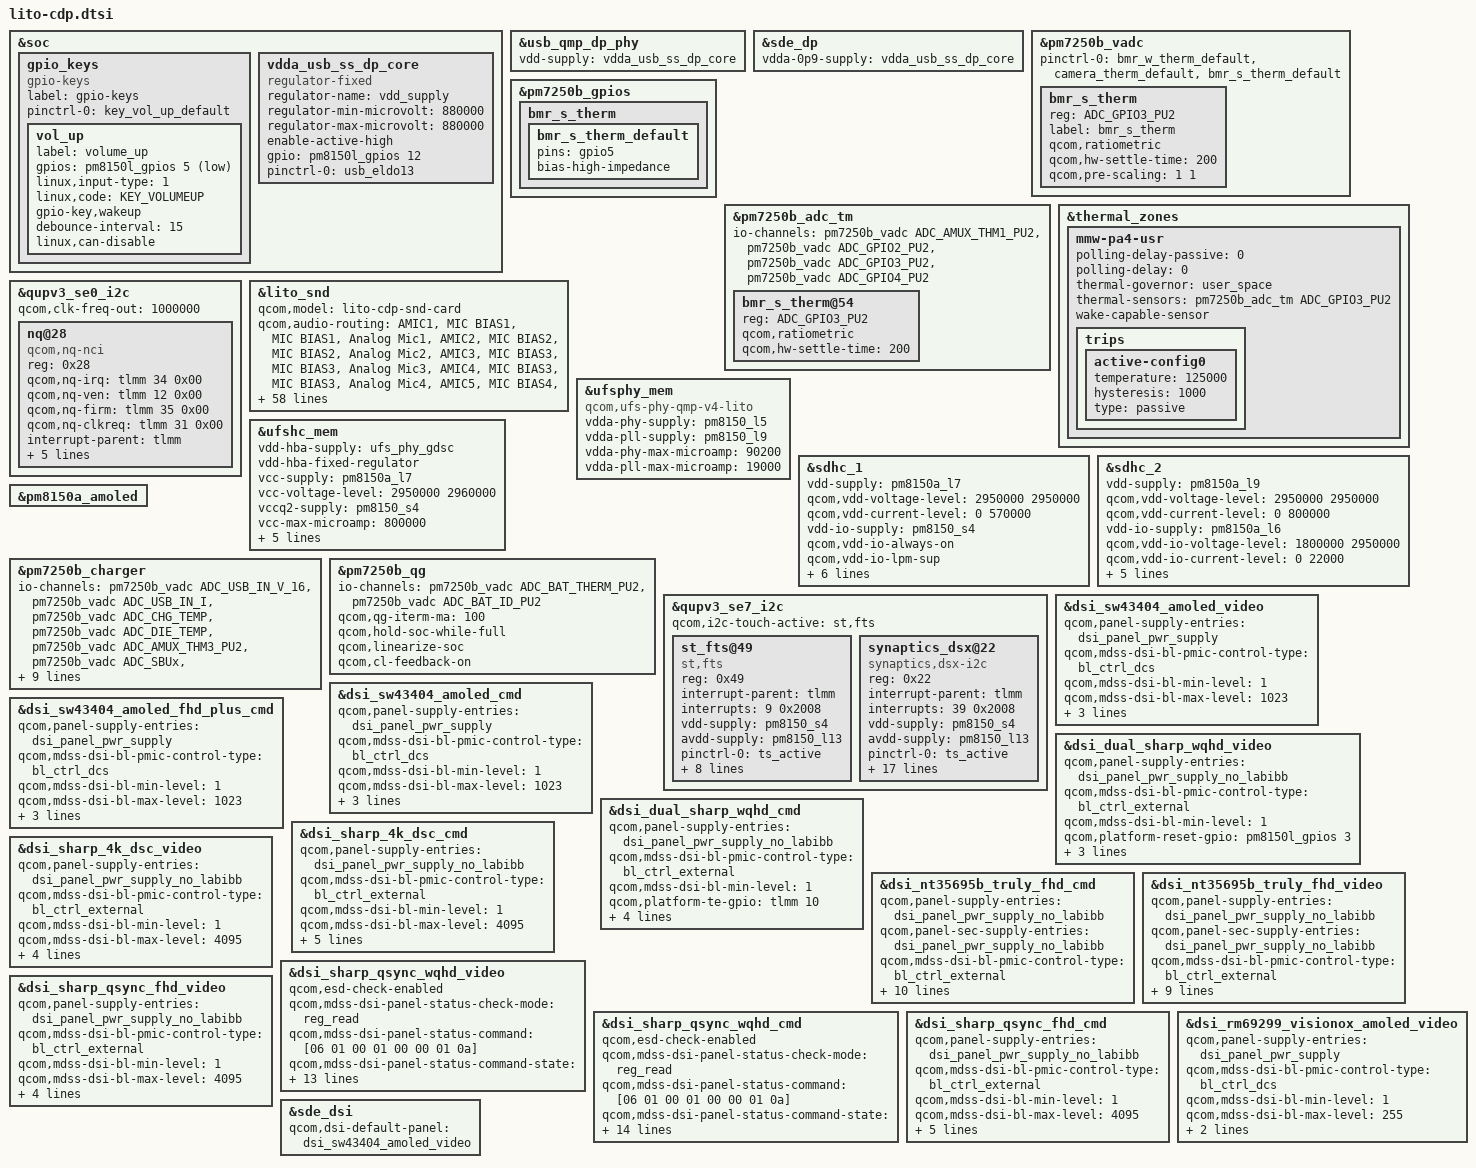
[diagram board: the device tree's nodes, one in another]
#include <dt-bindings/gpio/gpio.h>
#include "lito-audio-overlay.dtsi"
#include "lito-pmic-overlay.dtsi"
#include "camera/lito-camera-sensor-cdp.dtsi"
#include "lito-sde-display.dtsi"
#include "lito-thermal-overlay.dtsi"

&soc {
	gpio_keys {
		compatible = "gpio-keys";
		label = "gpio-keys";

		pinctrl-names = "default";
		pinctrl-0 = <&key_vol_up_default>;

		vol_up {
			label = "volume_up";
			gpios = <&pm8150l_gpios 5 GPIO_ACTIVE_LOW>;
			linux,input-type = <1>;
			linux,code = <KEY_VOLUMEUP>;
			gpio-key,wakeup;
			debounce-interval = <15>;
			linux,can-disable;
		};
	};

	vdda_usb_ss_dp_core: vdda_usb_ss_dp_core {
		compatible = "regulator-fixed";
		regulator-name = "vdd_supply";
		regulator-min-microvolt = <880000>;
		regulator-max-microvolt = <880000>;
		enable-active-high;
		gpio = <&pm8150l_gpios 12 GPIO_ACTIVE_HIGH>;
		pinctrl-names = "default";
		pinctrl-0 = <&usb_eldo13>;
	};
};

&usb_qmp_dp_phy {
	vdd-supply = <&vdda_usb_ss_dp_core>;
};

&sde_dp {
	vdda-0p9-supply = <&vdda_usb_ss_dp_core>;
};

&pm7250b_vadc {
	pinctrl-0 = <
		&bmr_w_therm_default
		&camera_therm_default
		&bmr_s_therm_default
	>;

	bmr_s_therm {
		reg = <ADC_GPIO3_PU2>;
		label = "bmr_s_therm";
		qcom,ratiometric;
		qcom,hw-settle-time = <200>;
		qcom,pre-scaling = <1 1>;
	};
};

&pm7250b_gpios {
	bmr_s_therm {
		bmr_s_therm_default: bmr_s_therm_default {
			pins = "gpio5";
			bias-high-impedance;
		};
	};
};

&pm7250b_adc_tm {
	io-channels = <&pm7250b_vadc ADC_AMUX_THM1_PU2>,
			<&pm7250b_vadc ADC_GPIO2_PU2>,
			<&pm7250b_vadc ADC_GPIO3_PU2>,
			<&pm7250b_vadc ADC_GPIO4_PU2>;

	bmr_s_therm@54 {
		reg = <ADC_GPIO3_PU2>;
		qcom,ratiometric;
		qcom,hw-settle-time = <200>;
	};
};

&thermal_zones {
	mmw-pa4-usr {
		polling-delay-passive = <0>;
		polling-delay = <0>;
		thermal-governor = "user_space";
		thermal-sensors = <&pm7250b_adc_tm ADC_GPIO3_PU2>;
		wake-capable-sensor;
		trips {
			active-config0 {
				temperature = <125000>;
				hysteresis = <1000>;
				type = "passive";
			};
		};
	};
};

&qupv3_se0_i2c {
	status = "ok";
	qcom,clk-freq-out = <1000000>;
	#address-cells = <1>;
	#size-cells = <0>;
	nq@28 {
		compatible = "qcom,nq-nci";
		reg = <0x28>;
		qcom,nq-irq = <&tlmm 34 0x00>;
		qcom,nq-ven = <&tlmm 12 0x00>;
		qcom,nq-firm = <&tlmm 35 0x00>;
		qcom,nq-clkreq = <&tlmm 31 0x00>;
		interrupt-parent = <&tlmm>;
		interrupts = <34 0>;
		interrupt-names = "nfc_irq";
		pinctrl-names = "nfc_active", "nfc_suspend";
		pinctrl-0 = <&nfc_int_active &nfc_enable_active
				&nfc_clk_req_active>;
		pinctrl-1 = <&nfc_int_suspend &nfc_enable_suspend
				&nfc_clk_req_suspend>;
	};
};

&lito_snd {
	qcom,model = "lito-cdp-snd-card";
	qcom,audio-routing =
		"AMIC1", "MIC BIAS1",
		"MIC BIAS1", "Analog Mic1",
		"AMIC2", "MIC BIAS2",
		"MIC BIAS2", "Analog Mic2",
		"AMIC3", "MIC BIAS3",
		"MIC BIAS3", "Analog Mic3",
		"AMIC4", "MIC BIAS3",
		"MIC BIAS3", "Analog Mic4",
		"AMIC5", "MIC BIAS4",
		"MIC BIAS4", "Analog Mic5",
		"TX DMIC0", "MIC BIAS3",
		"MIC BIAS3", "Digital Mic0",
		"TX DMIC1", "MIC BIAS3",
		"MIC BIAS3", "Digital Mic1",
		"TX DMIC2", "MIC BIAS1",
		"MIC BIAS1", "Digital Mic2",
		"TX DMIC3", "MIC BIAS1",
		"MIC BIAS1", "Digital Mic3",
		"TX DMIC4", "MIC BIAS4",
		"MIC BIAS4", "Digital Mic4",
		"TX DMIC5", "MIC BIAS4",
		"MIC BIAS4", "Digital Mic5",
		"DMIC1", "MIC BIAS3",
		"MIC BIAS3", "Digital Mic0",
		"DMIC2", "MIC BIAS3",
		"MIC BIAS3", "Digital Mic1",
		"DMIC3", "MIC BIAS1",
		"MIC BIAS1", "Digital Mic2",
		"DMIC4", "MIC BIAS1",
		"MIC BIAS1", "Digital Mic3",
		"DMIC5", "MIC BIAS4",
		"MIC BIAS4", "Digital Mic4",
		"DMIC6", "MIC BIAS4",
		"MIC BIAS4", "Digital Mic5",
		"DMIC7", "MIC BIAS3",
		"MIC BIAS3", "Digital Mic6",
		"DMIC8", "MIC BIAS3",
		"MIC BIAS3", "Digital Mic7",
		"IN1_HPHL", "HPHL_OUT",
		"IN2_HPHR", "HPHR_OUT",
		"IN3_AUX", "AUX_OUT",
		"TX SWR_ADC0", "ADC1_OUTPUT",
		"TX SWR_ADC1", "ADC2_OUTPUT",
		"TX SWR_ADC2", "ADC3_OUTPUT",
		"TX SWR_ADC3", "ADC4_OUTPUT",
		"TX SWR_DMIC0", "DMIC1_OUTPUT",
		"TX SWR_DMIC1", "DMIC2_OUTPUT",
		"TX SWR_DMIC2", "DMIC3_OUTPUT",
		"TX SWR_DMIC3", "DMIC4_OUTPUT",
		"TX SWR_DMIC4", "DMIC5_OUTPUT",
		"TX SWR_DMIC5", "DMIC6_OUTPUT",
		"TX SWR_DMIC6", "DMIC7_OUTPUT",
		"TX SWR_DMIC7", "DMIC8_OUTPUT",
		"WSA SRC0_INP", "SRC0",
		"WSA_TX DEC0_INP", "TX DEC0 MUX",
		"WSA_TX DEC1_INP", "TX DEC1 MUX",
		"RX_TX DEC0_INP", "TX DEC0 MUX",
		"RX_TX DEC1_INP", "TX DEC1 MUX",
		"RX_TX DEC2_INP", "TX DEC2 MUX",
		"RX_TX DEC3_INP", "TX DEC3 MUX",
		"SpkrLeft IN", "WSA_SPK1 OUT",
		"SpkrRight IN", "WSA_SPK2 OUT",
		"VA_AIF1 CAP", "VA_SWR_CLK",
		"VA_AIF2 CAP", "VA_SWR_CLK",
		"VA_AIF3 CAP", "VA_SWR_CLK",
		"VA MIC BIAS3", "Digital Mic0",
		"VA MIC BIAS3", "Digital Mic1",
		"VA MIC BIAS1", "Digital Mic2",
		"VA MIC BIAS1", "Digital Mic3",
		"VA MIC BIAS4", "Digital Mic4",
		"VA MIC BIAS4", "Digital Mic5",
		"VA DMIC0", "VA MIC BIAS3",
		"VA DMIC1", "VA MIC BIAS3",
		"VA DMIC2", "VA MIC BIAS1",
		"VA DMIC3", "VA MIC BIAS1",
		"VA DMIC4", "VA MIC BIAS4",
		"VA DMIC5", "VA MIC BIAS4",
		"VA SWR_ADC0", "VA_SWR_CLK",
		"VA SWR_ADC1", "VA_SWR_CLK",
		"VA SWR_ADC2", "VA_SWR_CLK",
		"VA SWR_ADC3", "VA_SWR_CLK",
		"VA SWR_MIC0", "VA_SWR_CLK",
		"VA SWR_MIC1", "VA_SWR_CLK",
		"VA SWR_MIC2", "VA_SWR_CLK",
		"VA SWR_MIC3", "VA_SWR_CLK",
		"VA SWR_MIC4", "VA_SWR_CLK",
		"VA SWR_MIC5", "VA_SWR_CLK",
		"VA SWR_MIC6", "VA_SWR_CLK",
		"VA SWR_MIC7", "VA_SWR_CLK",
		"VA SWR_ADC0", "ADC1_OUTPUT",
		"VA SWR_ADC1", "ADC2_OUTPUT",
		"VA SWR_ADC2", "ADC3_OUTPUT",
		"VA SWR_ADC3", "ADC4_OUTPUT",
		"VA SWR_MIC0", "DMIC1_OUTPUT",
		"VA SWR_MIC1", "DMIC2_OUTPUT",
		"VA SWR_MIC2", "DMIC3_OUTPUT",
		"VA SWR_MIC3", "DMIC4_OUTPUT",
		"VA SWR_MIC4", "DMIC5_OUTPUT",
		"VA SWR_MIC5", "DMIC6_OUTPUT",
		"VA SWR_MIC6", "DMIC7_OUTPUT",
		"VA SWR_MIC7", "DMIC8_OUTPUT";
};

&ufsphy_mem {
	compatible = "qcom,ufs-phy-qmp-v4-lito";

	vdda-phy-supply = <&pm8150_l5>;
	vdda-pll-supply = <&pm8150_l9>;
	vdda-phy-max-microamp = <90200>;
	vdda-pll-max-microamp = <19000>;

	status = "ok";
};

&ufshc_mem {
	vdd-hba-supply = <&ufs_phy_gdsc>;
	vdd-hba-fixed-regulator;
	vcc-supply = <&pm8150a_l7>;
	vcc-voltage-level = <2950000 2960000>;
	vccq2-supply = <&pm8150_s4>;
	vcc-max-microamp = <800000>;
	vccq2-max-microamp = <800000>;

	qcom,vddp-ref-clk-supply = <&pm8150_l9>;
	qcom,vddp-ref-clk-max-microamp = <100>;
	qcom,vddp-ref-clk-min-uV = <1152000>;
	qcom,vddp-ref-clk-max-uV = <1200000>;
	status = "ok";
};

&sdhc_1 {
	vdd-supply = <&pm8150a_l7>;
	qcom,vdd-voltage-level = <2950000 2950000>;
	qcom,vdd-current-level = <0 570000>;

	vdd-io-supply = <&pm8150_s4>;
	qcom,vdd-io-always-on;
	qcom,vdd-io-lpm-sup;
	qcom,vdd-io-voltage-level = <1800000 1800000>;
	qcom,vdd-io-current-level = <0 325000>;

	pinctrl-names = "active", "sleep";
	pinctrl-0 = <&sdc1_clk_on &sdc1_cmd_on &sdc1_data_on
					&sdc1_rclk_on>;
	pinctrl-1 = <&sdc1_clk_off &sdc1_cmd_off &sdc1_data_off
					&sdc1_rclk_off>;

	status = "ok";
};

&sdhc_2 {
	vdd-supply = <&pm8150a_l9>;
	qcom,vdd-voltage-level = <2950000 2950000>;
	qcom,vdd-current-level = <0 800000>;

	vdd-io-supply = <&pm8150a_l6>;
	qcom,vdd-io-voltage-level = <1800000 2950000>;
	qcom,vdd-io-current-level = <0 22000>;

	pinctrl-names = "active", "sleep";
	pinctrl-0 = <&sdc2_clk_on  &sdc2_cmd_on &sdc2_data_on &sdc2_cd_on>;
	pinctrl-1 = <&sdc2_clk_off &sdc2_cmd_off &sdc2_data_off &sdc2_cd_off>;

	cd-gpios = <&tlmm 69 GPIO_ACTIVE_LOW>;

	status = "ok";
};

&pm8150a_amoled {
	status = "ok";
};

&pm7250b_charger {
	status = "ok";
	io-channels = <&pm7250b_vadc ADC_USB_IN_V_16>,
		      <&pm7250b_vadc ADC_USB_IN_I>,
		      <&pm7250b_vadc ADC_CHG_TEMP>,
		      <&pm7250b_vadc ADC_DIE_TEMP>,
		      <&pm7250b_vadc ADC_AMUX_THM3_PU2>,
		      <&pm7250b_vadc ADC_SBUx>,
		      <&pm7250b_vadc ADC_VPH_PWR>;
	io-channel-names = "usb_in_voltage",
			   "usb_in_current",
			   "chg_temp",
			   "die_temp",
			   "conn_temp",
			   "sbux_res",
			   "vph_voltage";
	qcom,batteryless-platform;
	qcom,sec-charger-config = <1>;
	qcom,auto-recharge-soc = <98>;
	qcom,step-charging-enable;
	qcom,sw-jeita-enable;
	qcom,charger-temp-max = <800>;
	qcom,smb-temp-max = <800>;
	qcom,suspend-input-on-debug-batt;
};

&pm7250b_qg {
	status = "ok";
	io-channels = <&pm7250b_vadc ADC_BAT_THERM_PU2>,
		      <&pm7250b_vadc ADC_BAT_ID_PU2>;
	io-channel-names = "batt-therm",
			   "batt-id";
	qcom,qg-iterm-ma = <100>;
	qcom,hold-soc-while-full;
	qcom,linearize-soc;
	qcom,cl-feedback-on;
};

&qupv3_se7_i2c {
	#address-cells = <1>;
	#size-cells = <0>;

	status = "ok";
	qcom,i2c-touch-active = "st,fts";

	st_fts@49 {
		compatible = "st,fts";
		reg = <0x49>;
		interrupt-parent = <&tlmm>;
		interrupts = <9 0x2008>;
		vdd-supply = <&pm8150_s4>;
		avdd-supply = <&pm8150_l13>;
		pinctrl-names = "pmx_ts_active", "pmx_ts_suspend";
		pinctrl-0 = <&ts_active>;
		pinctrl-1 = <&ts_int_suspend &ts_reset_suspend>;
		st,irq-gpio = <&tlmm 9 0x2008>;
		st,reset-gpio = <&tlmm 8 0x00>;
		st,regulator_dvdd = "vdd";
		st,regulator_avdd = "avdd";
		panel = <&dsi_sw43404_amoled_cmd &dsi_sw43404_amoled_video
			 &dsi_sw43404_amoled_fhd_plus_cmd>;
	};

	synaptics_dsx@22 {
		compatible = "synaptics,dsx-i2c";
		reg = <0x22>;
		interrupt-parent = <&tlmm>;
		interrupts = <39 0x2008>;
		vdd-supply = <&pm8150_s4>;
		avdd-supply = <&pm8150_l13>;
		pinctrl-names = "pmx_ts_active", "pmx_ts_suspend",
							"pmx_ts_release";
		pinctrl-0 = <&ts_active>;
		pinctrl-1 = <&ts_int_suspend &ts_reset_suspend>;
		pinctrl-2 = <&pmx_ts_release>;
		synaptics,pwr-reg-name = "avdd";
		synaptics,bus-reg-name = "vdd";
		synaptics,ub-i2c-addr = <0x22>;
		synaptics,max-y-for-2d = <1859>;
		synaptics,irq-gpio = <&tlmm 9 0x2008>;
		synaptics,reset-gpio = <&tlmm 8 0x0>;
		synaptics,irq-on-state = <0>;
		synaptics,power-delay-ms = <200>;
		synaptics,reset-delay-ms = <200>;
		synaptics,reset-on-state = <0>;
		synaptics,reset-active-ms = <20>;

		panel = <&dsi_sharp_qsync_wqhd_cmd &dsi_sharp_qsync_wqhd_video
			&dsi_sharp_qsync_fhd_video &dsi_sharp_qsync_fhd_cmd>;
	};

};

&dsi_sw43404_amoled_video {
	qcom,panel-supply-entries = <&dsi_panel_pwr_supply>;
	qcom,mdss-dsi-bl-pmic-control-type = "bl_ctrl_dcs";
	qcom,mdss-dsi-bl-min-level = <1>;
	qcom,mdss-dsi-bl-max-level = <1023>;
	qcom,mdss-brightness-max-level = <255>;
	qcom,platform-te-gpio = <&tlmm 10 0>;
	qcom,platform-reset-gpio = <&pm8150l_gpios 3 0>;
};

&dsi_sw43404_amoled_cmd {
	qcom,panel-supply-entries = <&dsi_panel_pwr_supply>;
	qcom,mdss-dsi-bl-pmic-control-type = "bl_ctrl_dcs";
	qcom,mdss-dsi-bl-min-level = <1>;
	qcom,mdss-dsi-bl-max-level = <1023>;
	qcom,mdss-brightness-max-level = <255>;
	qcom,platform-te-gpio = <&tlmm 10 0>;
	qcom,platform-reset-gpio = <&pm8150l_gpios 3 0>;
};

&dsi_sw43404_amoled_fhd_plus_cmd {
	qcom,panel-supply-entries = <&dsi_panel_pwr_supply>;
	qcom,mdss-dsi-bl-pmic-control-type = "bl_ctrl_dcs";
	qcom,mdss-dsi-bl-min-level = <1>;
	qcom,mdss-dsi-bl-max-level = <1023>;
	qcom,mdss-brightness-max-level = <255>;
	qcom,platform-te-gpio = <&tlmm 10 0>;
	qcom,platform-reset-gpio = <&pm8150l_gpios 3 0>;
};

&dsi_dual_sharp_wqhd_video {
	qcom,panel-supply-entries = <&dsi_panel_pwr_supply_no_labibb>;
	qcom,mdss-dsi-bl-pmic-control-type = "bl_ctrl_external";
	qcom,mdss-dsi-bl-min-level = <1>;
	qcom,platform-reset-gpio = <&pm8150l_gpios 3 0>;
	qcom,platform-en-gpio = <&pm8150l_gpios 9 0>;
	qcom,platform-bklight-en-gpio = <&pm8150l_gpios 10 0>;
};

&dsi_dual_sharp_wqhd_cmd {
	qcom,panel-supply-entries = <&dsi_panel_pwr_supply_no_labibb>;
	qcom,mdss-dsi-bl-pmic-control-type = "bl_ctrl_external";
	qcom,mdss-dsi-bl-min-level = <1>;
	qcom,platform-te-gpio = <&tlmm 10 0>;
	qcom,platform-reset-gpio = <&pm8150l_gpios 3 0>;
	qcom,platform-en-gpio = <&pm8150l_gpios 9 0>;
	qcom,platform-bklight-en-gpio = <&pm8150l_gpios 10 0>;
};

&dsi_sharp_4k_dsc_cmd {
	qcom,panel-supply-entries = <&dsi_panel_pwr_supply_no_labibb>;
	qcom,mdss-dsi-bl-pmic-control-type = "bl_ctrl_external";
	qcom,mdss-dsi-bl-min-level = <1>;
	qcom,mdss-dsi-bl-max-level = <4095>;
	qcom,platform-te-gpio = <&tlmm 10 0>;
	qcom,platform-reset-gpio = <&pm8150l_gpios 3 0>;
	qcom,platform-en-gpio = <&pm8150l_gpios 9 0>;
	qcom,platform-bklight-en-gpio = <&pm8150l_gpios 10 0>;
};

&dsi_sharp_4k_dsc_video {
	qcom,panel-supply-entries = <&dsi_panel_pwr_supply_no_labibb>;
	qcom,mdss-dsi-bl-pmic-control-type = "bl_ctrl_external";
	qcom,mdss-dsi-bl-min-level = <1>;
	qcom,mdss-dsi-bl-max-level = <4095>;
	qcom,platform-reset-gpio = <&pm8150l_gpios 3 0>;
	qcom,platform-en-gpio = <&pm8150l_gpios 9 0>;
	qcom,platform-bklight-en-gpio = <&pm8150l_gpios 10 0>;
};

&dsi_nt35695b_truly_fhd_cmd {
	qcom,panel-supply-entries = <&dsi_panel_pwr_supply_no_labibb>;
	qcom,panel-sec-supply-entries = <&dsi_panel_pwr_supply_no_labibb>;
	qcom,mdss-dsi-bl-pmic-control-type = "bl_ctrl_external";
	qcom,mdss-dsi-sec-bl-pmic-control-type = "bl_ctrl_external";
	qcom,mdss-dsi-bl-min-level = <1>;
	qcom,mdss-dsi-bl-max-level = <4095>;
	qcom,platform-te-gpio = <&tlmm 10 0>;
	qcom,platform-reset-gpio = <&pm8150l_gpios 3 0>;
	qcom,platform-sec-reset-gpio = <&pm8150l_gpios 11 0>;
	qcom,platform-en-gpio = <&pm8150l_gpios 9 0>;
	qcom,platform-bklight-en-gpio = <&pm8150l_gpios 10 0>;
};

&dsi_nt35695b_truly_fhd_video {
	qcom,panel-supply-entries = <&dsi_panel_pwr_supply_no_labibb>;
	qcom,panel-sec-supply-entries = <&dsi_panel_pwr_supply_no_labibb>;
	qcom,mdss-dsi-bl-pmic-control-type = "bl_ctrl_external";
	qcom,mdss-dsi-sec-bl-pmic-control-type = "bl_ctrl_external";
	qcom,mdss-dsi-bl-min-level = <1>;
	qcom,mdss-dsi-bl-max-level = <4095>;
	qcom,platform-reset-gpio = <&pm8150l_gpios 3 0>;
	qcom,platform-sec-reset-gpio = <&pm8150l_gpios 11 0>;
	qcom,platform-en-gpio = <&pm8150l_gpios 9 0>;
	qcom,platform-bklight-en-gpio = <&pm8150l_gpios 10 0>;
};

&dsi_sharp_qsync_wqhd_video {
	qcom,esd-check-enabled;
	qcom,mdss-dsi-panel-status-check-mode = "reg_read";
	qcom,mdss-dsi-panel-status-command = [06 01 00 01 00 00 01 0a];
	qcom,mdss-dsi-panel-status-command-state = "dsi_lp_mode";
	qcom,mdss-dsi-panel-status-value = <0x9c>;
	qcom,mdss-dsi-panel-status-read-length = <1>;
	qcom,panel-supply-entries = <&dsi_panel_pwr_supply_no_labibb>;
	qcom,mdss-dsi-bl-pmic-control-type = "bl_ctrl_external";
	qcom,mdss-dsi-bl-min-level = <1>;
	qcom,mdss-dsi-bl-max-level = <4095>;
	qcom,platform-reset-gpio = <&pm8150l_gpios 3 0>;
	qcom,platform-en-gpio = <&pm8150l_gpios 9 0>;
	qcom,platform-bklight-en-gpio = <&pm8150l_gpios 10 0>;
};

&dsi_sharp_qsync_wqhd_cmd {
	qcom,esd-check-enabled;
	qcom,mdss-dsi-panel-status-check-mode = "reg_read";
	qcom,mdss-dsi-panel-status-command = [06 01 00 01 00 00 01 0a];
	qcom,mdss-dsi-panel-status-command-state = "dsi_lp_mode";
	qcom,mdss-dsi-panel-status-value = <0x9c>;
	qcom,mdss-dsi-panel-status-read-length = <1>;
	qcom,panel-supply-entries = <&dsi_panel_pwr_supply_no_labibb>;
	qcom,mdss-dsi-bl-pmic-control-type = "bl_ctrl_external";
	qcom,mdss-dsi-bl-min-level = <1>;
	qcom,mdss-dsi-bl-max-level = <4095>;
	qcom,platform-te-gpio = <&tlmm 10 0>;
	qcom,platform-reset-gpio = <&pm8150l_gpios 3 0>;
	qcom,platform-en-gpio = <&pm8150l_gpios 9 0>;
	qcom,platform-bklight-en-gpio = <&pm8150l_gpios 10 0>;
};

&dsi_sharp_qsync_fhd_video {
	qcom,panel-supply-entries = <&dsi_panel_pwr_supply_no_labibb>;
	qcom,mdss-dsi-bl-pmic-control-type = "bl_ctrl_external";
	qcom,mdss-dsi-bl-min-level = <1>;
	qcom,mdss-dsi-bl-max-level = <4095>;
	qcom,platform-reset-gpio = <&pm8150l_gpios 3 0>;
	qcom,platform-en-gpio = <&pm8150l_gpios 9 0>;
	qcom,platform-bklight-en-gpio = <&pm8150l_gpios 10 0>;
};

&dsi_sharp_qsync_fhd_cmd {
	qcom,panel-supply-entries = <&dsi_panel_pwr_supply_no_labibb>;
	qcom,mdss-dsi-bl-pmic-control-type = "bl_ctrl_external";
	qcom,mdss-dsi-bl-min-level = <1>;
	qcom,mdss-dsi-bl-max-level = <4095>;
	qcom,platform-te-gpio = <&tlmm 10 0>;
	qcom,platform-reset-gpio = <&pm8150l_gpios 3 0>;
	qcom,platform-en-gpio = <&pm8150l_gpios 9 0>;
	qcom,platform-bklight-en-gpio = <&pm8150l_gpios 10 0>;

};

&dsi_rm69299_visionox_amoled_video {
	qcom,panel-supply-entries = <&dsi_panel_pwr_supply>;
	qcom,mdss-dsi-bl-pmic-control-type = "bl_ctrl_dcs";
	qcom,mdss-dsi-bl-min-level = <1>;
	qcom,mdss-dsi-bl-max-level = <255>;
	qcom,platform-te-gpio = <&tlmm 10 0>;
	qcom,platform-reset-gpio = <&pm8150l_gpios 3 0>;
};

&sde_dsi {
	qcom,dsi-default-panel = <&dsi_sw43404_amoled_video>;
};

